# mcr_me13 register map
Registers are access not given, no defined reset value unless marked. A register's access mark holds for its fields unless they carry their own. Offsets are from the block's base; lines under a group give offsets from that group; [hi:lo] are bit positions; {n}, {i} and the like mark numbered series; 'fields as' and 'values as' point back to an identical list; <NAME> marks a mode.

## Memory map
0x40006C00 MCR size 0x400 — Misc Control.

## MCR — Misc Control.
Base 0x40006C00
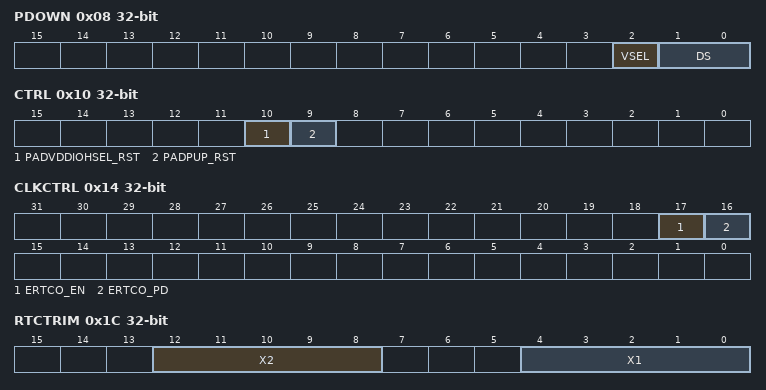
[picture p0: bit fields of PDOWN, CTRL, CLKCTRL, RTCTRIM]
0x08 PDOWN — PDOWN Drive Strength
  [2] VSEL — PDOWN Voltage Select
  [1:0] DS — PDOWN Drive Strength
0x10 CTRL — Control Register
  [10] PADVDDIOHSEL_RST — Reset VIDDIOH Select.
  [9] PADPUP_RST — Enable the Reset Pad Pull Up Resistors
    0=1m (1MOhm Pullup); 1=25k (25kOhm Pullup.)
0x14 CLKCTRL — System Clock Control Register
  [17] ERTCO_EN — ERTCO Enable.
  [16] ERTCO_PD — ERTCO Power Down.
0x18 RTCRST — Reset Register.
  [0] RTC — RTC Reset.
0x1C RTCTRIM
  [12:8] X2 — RTC Trim X2.
  [4:0] X1 — RTC Trim X1.
0x60 LDOCTRL — LDO Control Register.
  [0] 0P9V_EN — LDO 0.9V Enable.
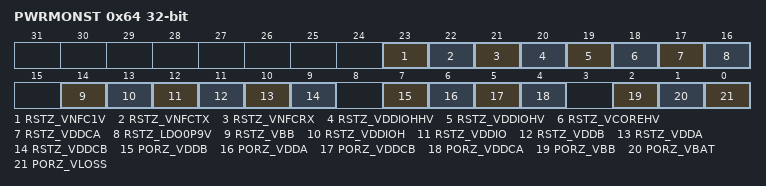
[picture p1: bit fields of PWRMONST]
0x64 PWRMONST — LDO Control Register.
  [23] RSTZ_VNFC1V — Sticky bit indicating reset condition on VNFC1V supply.
  [22] RSTZ_VNFCTX — Sticky bit indicating reset condition on VNFCTX supply.
  [21] RSTZ_VNFCRX — Sticky bit indicating reset condition on VNFCRX supply.
  [20] RSTZ_VDDIOHHV — Sticky bit indicating high voltage reset condition on VDDIOH supply.
  [19] RSTZ_VDDIOHV — Sticky bit indicating high voltage reset condition on VDDIO supply.
  [18] RSTZ_VCOREHV — Sticky bit indicating high voltage reset condition on VCORE supply.
  [17] RSTZ_VDDCA — Sticky bit indicating reset condition on VCORE in Analog supply.
  [16] RSTZ_LDO0P9V — Sticky bit indicating reset condition on 0.9V USB supply.
  [14] RSTZ_VBB — Sticky bit indicating reset condition on VBB supply.
  [13] RSTZ_VDDIOH — Sticky bit indicating reset condition on VDDIOH supply.
  [12] RSTZ_VDDIO — Sticky bit indicating reset condition on VDDIO supply.
  [11] RSTZ_VDDB — Sticky bit indicating reset condition on VDDB (USB) supply.
  [10] RSTZ_VDDA — Sticky bit indicating reset condition on VDDA (analog) supply.
  [9] RSTZ_VDDCB — Sticky bit indicating reset condition on VCORE supply.
  [7] PORZ_VDDB — Sticky bit indicating power-on status of VDDB (for USB) supply.
  [6] PORZ_VDDA — Sticky bit indicating power-on status of VDDA (for analog) supply.
  [5] PORZ_VDDCB — Sticky bit indicating power-on status of VCORE_PAD supply.
  [4] PORZ_VDDCA — Sticky bit indicating power-on status of VAON_SW supply.
  [2] PORZ_VBB — Sticky bit indicating power-on status of the VBB.
  [1] PORZ_VBAT — Sticky bit indicating power-on status of the battery.
  [0] PORZ_VLOSS — Sticky bit indicating power-on status of core power domains of VDDIO, VDDIOH, VCOR
